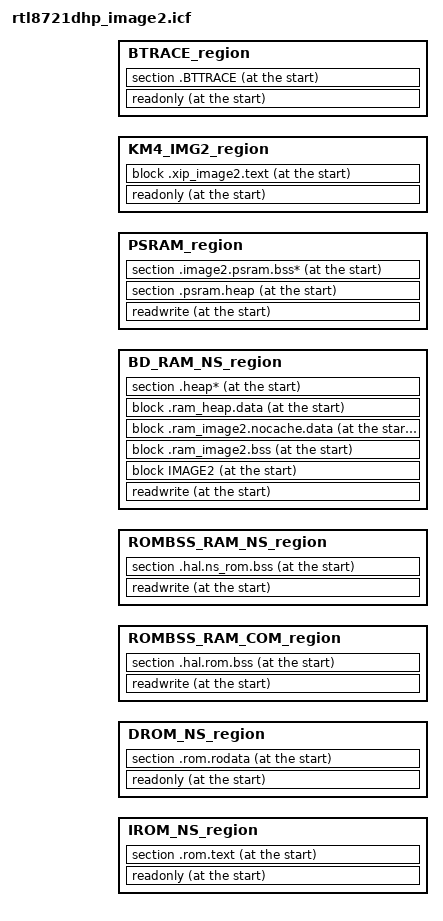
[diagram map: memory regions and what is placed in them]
/*###ICF### Section handled by ICF editor, don't touch! ****/
/*-Editor annotation file-*/
/* IcfEditorFile="$TOOLKIT_DIR$\config\ide\IcfEditor\cortex_v1_0.xml" */
/*-Specials-*/

include "rtl8721dhp_rom_symbol_ns.icf";
include "rtl8721d_memory_layout.icf";

/*-Sizes-*/
/*define symbol __ICFEDIT_size_cstack__   = 0x400;*/
/*define symbol __ICFEDIT_size_heap__     = 0x800;*/
/**** End of ICF editor section. ###ICF###*/

define memory mem with size = 4G;
define region IROM_region   		= mem:[from __ICFEDIT_region_HS_IROM_start__   to __ICFEDIT_region_HS_IROM_end__];
define region IROM_NS_region   		= mem:[from __ICFEDIT_region_HS_IROM_NS_start__   to __ICFEDIT_region_HS_IROM_NS_end__];
define region DROM_NS_region   		= mem:[from __ICFEDIT_region_HS_DROM_NS_start__   to __ICFEDIT_region_HS_DROM_NS_end__];
define region DROM_region  		= mem:[from __ICFEDIT_region_HS_DROM_start__   to __ICFEDIT_region_HS_DROM_end__];
define region ROMBSS_RAM_COM_region   	= mem:[from __ICFEDIT_region_HS_ROMBSS_RAM_COM_start__   to __ICFEDIT_region_HS_ROMBSS_RAM_COM_end__];
define region ROMBSS_RAM_NS_region   	= mem:[from __ICFEDIT_region_HS_ROMBSS_RAM_NS_start__   to __ICFEDIT_region_HS_ROMBSS_RAM_NS_end__];
define region RSVD_RAM_NS_region   	= mem:[from __ICFEDIT_region_HS_RSVD_RAM_NS_start__   to __ICFEDIT_region_HS_RSVD_RAM_NS_end__];
define region MSP_RAM_NS_region   	= mem:[from __ICFEDIT_region_HS_MSP_RAM_NS_start__   to __ICFEDIT_region_HS_MSP_RAM_NS_end__];
define region BD_RAM_NS_region   	= mem:[from __ICFEDIT_region_HS_BD_RAM_NS_start__   to __ICFEDIT_region_HS_BD_RAM_NS_end__];
define region BD_RAM_S_region   	= mem:[from __ICFEDIT_region_HS_BD_RAM_S_start__   to __ICFEDIT_region_HS_BD_RAM_S_end__];
define region BD_RAM_NSC_region   	= mem:[from __ICFEDIT_region_HS_BD_RAM_NSC_start__   to __ICFEDIT_region_HS_BD_RAM_NSC_end__];
define region ROMBSS_RAM_S_region   	= mem:[from __ICFEDIT_region_HS_ROMBSS_RAM_S_start__   to __ICFEDIT_region_HS_ROMBSS_RAM_S_end__];
define region BOOTLOADER_RAM_S_region   = mem:[from __ICFEDIT_region_HS_BOOTLOADER_RAM_S_start__   to __ICFEDIT_region_HS_BOOTLOADER_RAM_S_end__];
define region MSP_RAM_S_region   	= mem:[from __ICFEDIT_region_HS_MSP_RAM_S_start__   to __ICFEDIT_region_HS_MSP_RAM_S_end__];
define region EXTENTION_SRAM_region   	= mem:[from __ICFEDIT_region_HS_EXTENTION_SRAM_start__   to __ICFEDIT_region_HS_EXTENTION_SRAM_end__];
define region PSRAM_region   		= mem:[from __ICFEDIT_region_HS_PSRAM_NS_start__   to __ICFEDIT_region_HS_PSRAM_NS_end__];
define region KM4_BOOT_region   	= mem:[from __ICFEDIT_region_HS_FLASH_BOOT_start__   to __ICFEDIT_region_HS_FLASH_BOOT_end__];
define region KM4_IMG2_region   	= mem:[from __ICFEDIT_region_HS_FLASH_IMG2_start__   to __ICFEDIT_region_HS_FLASH_IMG2_end__];
define region BTRACE_region   		= mem:[from __ICFEDIT_region_HS_BTRACE_start__   to __ICFEDIT_region_HS_BTRACE_end__];
define region RETENTION_RAM_region   	= mem:[from __ICFEDIT_region_RETENTION_RAM_start__   to __ICFEDIT_region_RETENTION_RAM_end__];


/*define block CSTACK    with alignment = 8, size = __ICFEDIT_size_cstack__   { };*/
/*define block HEAP      with alignment = 8, size = __ICFEDIT_size_heap__     { };*/

//initialize by copy { readwrite };
//initialize by copy with packing = none { section __DLIB_PERTHREAD }; // Required in a multi-threaded application

//do not initialize  { section * };

/****************************************
 * ROM Section config                   *
 ****************************************/
keep { section .rom.text };
place at start of IROM_NS_region   { readonly, section .rom.text };

keep { section .rom.rodata };
place at start of DROM_NS_region   { readonly, section .rom.rodata };

/****************************************
 * ROM BSS Section config                *
 ****************************************/
keep { section .hal.rom.bss };
place at start of ROMBSS_RAM_COM_region  { readwrite, section .hal.rom.bss };

keep { section .hal.ns_rom.bss };
place at start of ROMBSS_RAM_NS_region  { readwrite, section .hal.ns_rom.bss };

/****************************************
 * BD RAM Section config                *
 ****************************************/
keep { section .image2.entry.data* };
keep { section .image2.validate.rodata* };
define block .ram_image2.entry with fixed order{section .image2.entry.data*,
						section .image2.validate.rodata*,
						};

define block .ram_image2.text with fixed order{section .image2.ram.text*};

define block SHT$$PREINIT_ARRAY { preinit_array };
define block SHT$$INIT_ARRAY { init_array };
define block CPP_INIT with fixed order { block SHT$$PREINIT_ARRAY,
					block SHT$$INIT_ARRAY };
define block .ram_image2.data with fixed order{ section .data*,
						section DATA, 
						section .iar.init_table,
						section __DLIB_PERTHREAD,
                                                block CPP_INIT,
						};

define block IMAGE2 with fixed order { block .ram_image2.entry,
                                       block .ram_image2.text,
                                       block .ram_image2.data,
};

define block .ram_image2.bss with fixed order{section .bss*,
					      section COMMON,
					     };


define block .ram_image2.nocache.data with alignment = 32 {section .bdsram.data*};


define block .ram_heap.data with fixed order { section .bfsram.data*,
                                               section .heap.stdlib*,
                                             };

place at start of BD_RAM_NS_region   { readwrite, 
                                    block IMAGE2,
                                    block .ram_image2.bss,
                                    block .ram_image2.nocache.data,
                                    block .ram_heap.data,
                                    section .heap*
                                  };

/****************************************
 * XIP Image2 Section config                *
 ****************************************/
keep { section .cmd.table.data* };
define block .xip_image2.text with fixed order{ section .img2_custom_signature*,
                                                section .text*,
                                                section .rodata*,
                                                section .cmd.table.data*,
                                                section .debug_trace,
						section CODE,
						section Veneer,
                                              };

place at start of KM4_IMG2_region   {  readonly,
					 block .xip_image2.text };

/****************************************
 * BT Trace Section config                *
 ****************************************/
place at start of BTRACE_region   {  readonly,
					 section .BTTRACE };

/****************************************
 * PSRAM Section config                *
 ****************************************/
place at start of PSRAM_region   {  readwrite,
					 section .psram.heap,
                                         section .image2.psram.bss* };


//define exported symbol __ram_start_table_start__= 0x10002000;	// use in rom
//define exported symbol __image1_validate_code__= 0x10002018;	// needed by ram code
//define exported symbol __rom_top_4k_start_= 0x1003F000;	// needed by ram code
//define exported symbol __flash_text_start__= 0x0800b020; // needed by ram code

//define exported symbol __ram_image3_start__=__ICFEDIT_region_BD_RAM_S_start__;
//define exported symbol __ram_image3_end__=__ICFEDIT_region_BD_RAM_S_end__;
//define exported symbol __flash_text_start__=__ICFEDIT_region_KM4_IMG2_start__;
